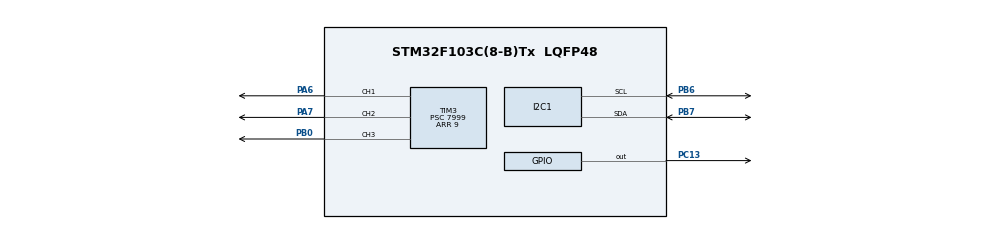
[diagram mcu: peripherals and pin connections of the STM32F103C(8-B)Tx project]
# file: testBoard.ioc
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Mcu.Family=STM32F1
Mcu.Name=STM32F103C(8-B)Tx
Mcu.Package=LQFP48
NVIC.PriorityGroup=NVIC_PRIORITYGROUP_4
NVIC.TIM3_IRQn=true\:0\:0\:false\:false\:true\:true\:true
PA13.Mode=Serial_Wire
PA13.Signal=SYS_JTMS-SWDIO
PA14.Mode=Serial_Wire
PA14.Signal=SYS_JTCK-SWCLK
PA6.Signal=S_TIM3_CH1
PA7.Signal=S_TIM3_CH2
PB0.Signal=S_TIM3_CH3
PB6.Mode=I2C
PB6.Signal=I2C1_SCL
PB7.Mode=I2C
PB7.Signal=I2C1_SDA
PC13-TAMPER-RTC.Signal=GPIO_Output
ProjectManager.HeapSize=0x200
ProjectManager.StackSize=0x400
ProjectManager.TargetToolchain=STM32CubeIDE
RCC.APB1Freq_Value=8000000
RCC.APB2Freq_Value=8000000
SH.S_TIM3_CH1.0=TIM3_CH1,PWM Generation1 CH1
SH.S_TIM3_CH2.0=TIM3_CH2,PWM Generation2 CH2
SH.S_TIM3_CH3.0=TIM3_CH3,PWM Generation3 CH3
TIM3.Channel-PWM\ Generation1\ CH1=TIM_CHANNEL_1
TIM3.Channel-PWM\ Generation2\ CH2=TIM_CHANNEL_2
TIM3.Channel-PWM\ Generation3\ CH3=TIM_CHANNEL_3
TIM3.Period=9
TIM3.Prescaler=7999
VP_TIM3_VS_ClockSourceINT.Mode=Internal
board=custom

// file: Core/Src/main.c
/* USER CODE BEGIN Header */
/**
  ******************************************************************************
  * @file           : main.c
  * @brief          : Main program body
  ******************************************************************************
  * @attention
  *
  * <h2><center>&copy; Copyright (c) 2024 STMicroelectronics.
  * All rights reserved.</center></h2>
  *
  * This software component is licensed by ST under BSD 3-Clause license,
  * the "License"; You may not use this file except in compliance with the
  * License. You may obtain a copy of the License at:
  *                        opensource.org/licenses/BSD-3-Clause
  *
  ******************************************************************************
  */
/* USER CODE END Header */
#include "main.h"

/* USER CODE BEGIN Includes */
#include "global.h"
/* USER CODE END Includes */

I2C_HandleTypeDef hi2c1;

TIM_HandleTypeDef htim3;

void SystemClock_Config(void);
static void MX_GPIO_Init(void);
static void MX_I2C1_Init(void);
static void MX_TIM3_Init(void);

int main(void)
{

  /* MCU Configuration--------------------------------------------------------*/

  /* Reset of all peripherals, Initializes the Flash interface and the Systick. */
  HAL_Init();

  /* Configure the system clock */
  SystemClock_Config();

  /* Initialize all configured peripherals */
  MX_GPIO_Init();
  MX_I2C1_Init();
  MX_TIM3_Init();
  /* USER CODE BEGIN 2 */
  HAL_TIM_Base_Start_IT(&htim3);

  HAL_TIM_PWM_Start(&htim3, TIM_CHANNEL_1);		//Red
  HAL_TIM_PWM_Start(&htim3, TIM_CHANNEL_2);		//Green
  HAL_TIM_PWM_Start(&htim3, TIM_CHANNEL_3);		//Blue
  /* USER CODE END 2 */

  /* Infinite loop */
  /* USER CODE BEGIN WHILE */
  lcd_init();
  lcd_clear_display();

//  uint32_t currentTime = 0;
//  uint32_t previousTime = 0;

//  float temperature = 26.5;
//  float humidity = 60.3;

  setTimerForFSM(2000);

  while (1)
  {
    /* USER CODE END WHILE */

    /* USER CODE BEGIN 3 */
	  fsm_run();
	  HAL_Delay(10);

	  //-----------TEST BOARD---------------------
//	  currentTime = HAL_GetTick();
//	  if (currentTime - previousTime >= 500) {
//		  HAL_GPIO_TogglePin(GPIOC, GPIO_PIN_13);
//		  previousTime = currentTime;
//	  }
	  //-----------TEST BOARD--------------------

	  //-----------TEST TIMER--------------------
//	  if (fsm_flag == 1) {
//		  setTimerForFSM(200);
//		  //TODO
//		  HAL_GPIO_TogglePin(GPIOC, GPIO_PIN_13);
//	  }
	  //-----------TEST TIMER--------------------

	  //---------------TEST LCD-------------------------
//	  lcd_goto_XY(1, 0);
//	  lcd_send_string("Initializing");
//	  HAL_Delay(1000);
//	  lcd_goto_XY(1, 0);
//	  lcd_send_string("Nhiet do: ");
//	  lcd_goto_XY(1, 10);
//	  lcd_send_float(temperature);
//	  lcd_goto_XY(2, 0);
//	  lcd_send_string("Do am: ");
//	  lcd_goto_XY(2, 7);
//	  lcd_send_float(humidity);
	  //---------------TEST LCD-------------------------

	  //---------------TEST RGB-------------------------

//	  ledRGB(MAX_DUTY, MAX_DUTY, MAX_DUTY);		//white

	  //Red;
//	  ledRGB(MAX_DUTY, 0, 0);
//	  HAL_Delay(1000);
//	  //Green
//	  ledRGB(0, MAX_DUTY, 0);
//	  HAL_Delay(1000);
//	  //Blue
//	  ledRGB(0, 0, MAX_DUTY);
//	  HAL_Delay(1000);

	  //---------------TEST RGB-------------------------

  }
  /* USER CODE END 3 */
}

void SystemClock_Config(void)
{
  RCC_OscInitTypeDef RCC_OscInitStruct = {0};
  RCC_ClkInitTypeDef RCC_ClkInitStruct = {0};

  /** Initializes the RCC Oscillators according to the specified parameters
  * in the RCC_OscInitTypeDef structure.
  */
  RCC_OscInitStruct.OscillatorType = RCC_OSCILLATORTYPE_HSI;
  RCC_OscInitStruct.HSIState = RCC_HSI_ON;
  RCC_OscInitStruct.HSICalibrationValue = RCC_HSICALIBRATION_DEFAULT;
  RCC_OscInitStruct.PLL.PLLState = RCC_PLL_NONE;
  if (HAL_RCC_OscConfig(&RCC_OscInitStruct) != HAL_OK)
  {
    Error_Handler();
  }
  /** Initializes the CPU, AHB and APB buses clocks
  */
  RCC_ClkInitStruct.ClockType = RCC_CLOCKTYPE_HCLK|RCC_CLOCKTYPE_SYSCLK
                              |RCC_CLOCKTYPE_PCLK1|RCC_CLOCKTYPE_PCLK2;
  RCC_ClkInitStruct.SYSCLKSource = RCC_SYSCLKSOURCE_HSI;
  RCC_ClkInitStruct.AHBCLKDivider = RCC_SYSCLK_DIV1;
  RCC_ClkInitStruct.APB1CLKDivider = RCC_HCLK_DIV1;
  RCC_ClkInitStruct.APB2CLKDivider = RCC_HCLK_DIV1;

  if (HAL_RCC_ClockConfig(&RCC_ClkInitStruct, FLASH_LATENCY_0) != HAL_OK)
  {
    Error_Handler();
  }
}

static void MX_I2C1_Init(void)
{

  hi2c1.Instance = I2C1;
  hi2c1.Init.ClockSpeed = 100000;
  hi2c1.Init.DutyCycle = I2C_DUTYCYCLE_2;
  hi2c1.Init.OwnAddress1 = 0;
  hi2c1.Init.AddressingMode = I2C_ADDRESSINGMODE_7BIT;
  hi2c1.Init.DualAddressMode = I2C_DUALADDRESS_DISABLE;
  hi2c1.Init.OwnAddress2 = 0;
  hi2c1.Init.GeneralCallMode = I2C_GENERALCALL_DISABLE;
  hi2c1.Init.NoStretchMode = I2C_NOSTRETCH_DISABLE;
  if (HAL_I2C_Init(&hi2c1) != HAL_OK)
  {
    Error_Handler();
  }

}

static void MX_TIM3_Init(void)
{

  TIM_ClockConfigTypeDef sClockSourceConfig = {0};
  TIM_MasterConfigTypeDef sMasterConfig = {0};
  TIM_OC_InitTypeDef sConfigOC = {0};

  htim3.Instance = TIM3;
  htim3.Init.Prescaler = 7999;
  htim3.Init.CounterMode = TIM_COUNTERMODE_UP;
  htim3.Init.Period = 9;
  htim3.Init.ClockDivision = TIM_CLOCKDIVISION_DIV1;
  htim3.Init.AutoReloadPreload = TIM_AUTORELOAD_PRELOAD_DISABLE;
  if (HAL_TIM_Base_Init(&htim3) != HAL_OK)
  {
    Error_Handler();
  }
  sClockSourceConfig.ClockSource = TIM_CLOCKSOURCE_INTERNAL;
  if (HAL_TIM_ConfigClockSource(&htim3, &sClockSourceConfig) != HAL_OK)
  {
    Error_Handler();
  }
  if (HAL_TIM_PWM_Init(&htim3) != HAL_OK)
  {
    Error_Handler();
  }
  sMasterConfig.MasterOutputTrigger = TIM_TRGO_RESET;
  sMasterConfig.MasterSlaveMode = TIM_MASTERSLAVEMODE_DISABLE;
  if (HAL_TIMEx_MasterConfigSynchronization(&htim3, &sMasterConfig) != HAL_OK)
  {
    Error_Handler();
  }
  sConfigOC.OCMode = TIM_OCMODE_PWM1;
  sConfigOC.Pulse = 0;
  sConfigOC.OCPolarity = TIM_OCPOLARITY_HIGH;
  sConfigOC.OCFastMode = TIM_OCFAST_DISABLE;
  if (HAL_TIM_PWM_ConfigChannel(&htim3, &sConfigOC, TIM_CHANNEL_1) != HAL_OK)
  {
    Error_Handler();
  }
  if (HAL_TIM_PWM_ConfigChannel(&htim3, &sConfigOC, TIM_CHANNEL_2) != HAL_OK)
  {
    Error_Handler();
  }
  if (HAL_TIM_PWM_ConfigChannel(&htim3, &sConfigOC, TIM_CHANNEL_3) != HAL_OK)
  {
    Error_Handler();
  }
  HAL_TIM_MspPostInit(&htim3);

}

static void MX_GPIO_Init(void)
{
  GPIO_InitTypeDef GPIO_InitStruct = {0};

  /* GPIO Ports Clock Enable */
  __HAL_RCC_GPIOC_CLK_ENABLE();
  __HAL_RCC_GPIOA_CLK_ENABLE();
  __HAL_RCC_GPIOB_CLK_ENABLE();

  /*Configure GPIO pin Output Level */
  HAL_GPIO_WritePin(GPIOC, GPIO_PIN_13, GPIO_PIN_RESET);

  /*Configure GPIO pin : PC13 */
  GPIO_InitStruct.Pin = GPIO_PIN_13;
  GPIO_InitStruct.Mode = GPIO_MODE_OUTPUT_PP;
  GPIO_InitStruct.Pull = GPIO_NOPULL;
  GPIO_InitStruct.Speed = GPIO_SPEED_FREQ_LOW;
  HAL_GPIO_Init(GPIOC, &GPIO_InitStruct);

}

/* USER CODE BEGIN 4 */
void HAL_TIM_PeriodElapsedCallback(TIM_HandleTypeDef *htim)
{
	timerRun();
}
/* USER CODE END 4 */

void Error_Handler(void)
{
  __disable_irq();
  while (1)
  {
  }
}

/************************ (C) COPYRIGHT STMicroelectronics *****END OF FILE****/
